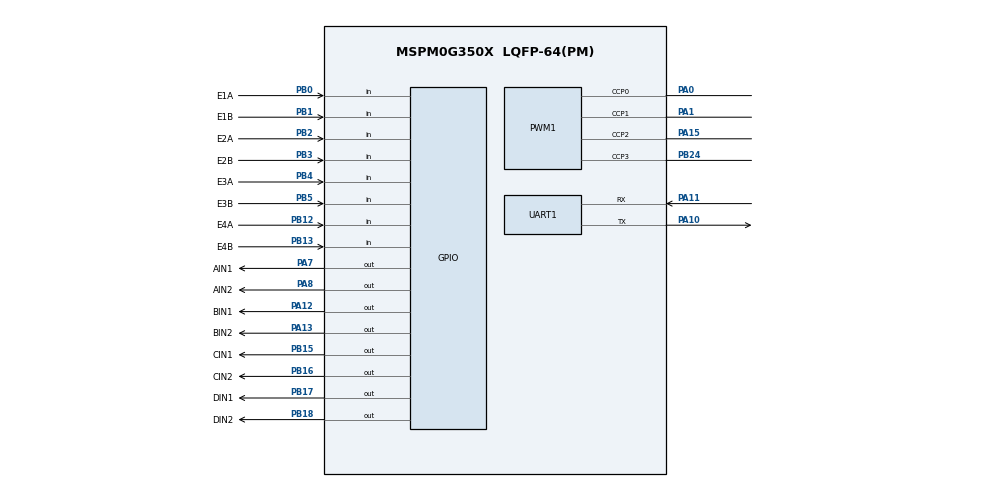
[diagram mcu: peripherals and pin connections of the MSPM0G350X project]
/**
 * @cliArgs --device "MSPM0G350X" --part "Default" --package "LQFP-64(PM)" --product "mspm0_sdk@2.11.00.07"
 * @versions {"tool":"1.27.1+4634"}
 */

/**
 * Import the modules used in this configuration.
 */
const GPIO   = scripting.addModule("/ti/driverlib/GPIO", {}, false);
const GPIO1  = GPIO.addInstance();
const GPIO2  = GPIO.addInstance();
const GPIO3  = GPIO.addInstance();
const GPIO4  = GPIO.addInstance();
const PWM    = scripting.addModule("/ti/driverlib/PWM", {}, false);
const PWM1   = PWM.addInstance();
const SYSCTL = scripting.addModule("/ti/driverlib/SYSCTL");
const TIMER  = scripting.addModule("/ti/driverlib/TIMER", {}, false);
const TIMER1 = TIMER.addInstance();
const UART   = scripting.addModule("/ti/driverlib/UART", {}, false);
const UART1  = UART.addInstance();

/**
 * Write custom configuration values to the imported modules.
 */
const divider9       = system.clockTree["UDIV"];
divider9.divideValue = 2;

const mux4       = system.clockTree["EXHFMUX"];
mux4.inputSelect = "EXHFMUX_XTAL";

const mux8       = system.clockTree["HSCLKMUX"];
mux8.inputSelect = "HSCLKMUX_SYSPLL2X";

const mux12       = system.clockTree["SYSPLLMUX"];
mux12.inputSelect = "zSYSPLLMUX_HFCLK";

const pinFunction4        = system.clockTree["HFXT"];
pinFunction4.inputFreq    = 40;
pinFunction4.enable       = true;
pinFunction4.HFCLKMonitor = true;
pinFunction4.HFXTStartup  = 20;

GPIO1.$name                          = "LED";
GPIO1.associatedPins[0].$name        = "PIN_0";
GPIO1.associatedPins[0].assignedPort = "PORTB";
GPIO1.associatedPins[0].assignedPin  = "22";
GPIO1.associatedPins[0].ioStructure  = "SD";

const Board = scripting.addModule("/ti/driverlib/Board", {}, false);

GPIO2.$name                               = "Encoder";
GPIO2.port                                = "PORTB";
GPIO2.associatedPins.create(8);
GPIO2.associatedPins[0].$name             = "E1A";
GPIO2.associatedPins[0].direction         = "INPUT";
GPIO2.associatedPins[0].internalResistor  = "PULL_UP";
GPIO2.associatedPins[0].interruptEn       = true;
GPIO2.associatedPins[0].polarity          = "RISE_FALL";
GPIO2.associatedPins[0].inputFilter       = "8_CYCLES";
GPIO2.associatedPins[0].interruptPriority = "3";
GPIO2.associatedPins[0].pin.$assign       = "PB0";
GPIO2.associatedPins[1].$name             = "E1B";
GPIO2.associatedPins[1].direction         = "INPUT";
GPIO2.associatedPins[1].internalResistor  = "PULL_UP";
GPIO2.associatedPins[1].interruptEn       = true;
GPIO2.associatedPins[1].polarity          = "RISE_FALL";
GPIO2.associatedPins[1].inputFilter       = "8_CYCLES";
GPIO2.associatedPins[1].interruptPriority = "3";
GPIO2.associatedPins[1].pin.$assign       = "PB1";
GPIO2.associatedPins[2].$name             = "E2A";
GPIO2.associatedPins[2].direction         = "INPUT";
GPIO2.associatedPins[2].internalResistor  = "PULL_UP";
GPIO2.associatedPins[2].interruptEn       = true;
GPIO2.associatedPins[2].polarity          = "RISE_FALL";
GPIO2.associatedPins[2].inputFilter       = "8_CYCLES";
GPIO2.associatedPins[2].interruptPriority = "3";
GPIO2.associatedPins[2].pin.$assign       = "PB2";
GPIO2.associatedPins[3].$name             = "E2B";
GPIO2.associatedPins[3].direction         = "INPUT";
GPIO2.associatedPins[3].internalResistor  = "PULL_UP";
GPIO2.associatedPins[3].interruptEn       = true;
GPIO2.associatedPins[3].polarity          = "RISE_FALL";
GPIO2.associatedPins[3].inputFilter       = "8_CYCLES";
GPIO2.associatedPins[3].interruptPriority = "3";
GPIO2.associatedPins[3].pin.$assign       = "PB3";
GPIO2.associatedPins[4].$name             = "E3A";
GPIO2.associatedPins[4].direction         = "INPUT";
GPIO2.associatedPins[4].internalResistor  = "PULL_UP";
GPIO2.associatedPins[4].interruptEn       = true;
GPIO2.associatedPins[4].polarity          = "RISE_FALL";
GPIO2.associatedPins[4].inputFilter       = "8_CYCLES";
GPIO2.associatedPins[4].interruptPriority = "3";
GPIO2.associatedPins[4].pin.$assign       = "PB4";
GPIO2.associatedPins[5].$name             = "E3B";
GPIO2.associatedPins[5].direction         = "INPUT";
GPIO2.associatedPins[5].internalResistor  = "PULL_UP";
GPIO2.associatedPins[5].interruptEn       = true;
GPIO2.associatedPins[5].polarity          = "RISE_FALL";
GPIO2.associatedPins[5].inputFilter       = "8_CYCLES";
GPIO2.associatedPins[5].interruptPriority = "3";
GPIO2.associatedPins[5].pin.$assign       = "PB5";
GPIO2.associatedPins[6].$name             = "E4A";
GPIO2.associatedPins[6].direction         = "INPUT";
GPIO2.associatedPins[6].internalResistor  = "PULL_UP";
GPIO2.associatedPins[6].interruptEn       = true;
GPIO2.associatedPins[6].polarity          = "RISE_FALL";
GPIO2.associatedPins[6].inputFilter       = "8_CYCLES";
GPIO2.associatedPins[6].interruptPriority = "3";
GPIO2.associatedPins[6].pin.$assign       = "PB12";
GPIO2.associatedPins[7].$name             = "E4B";
GPIO2.associatedPins[7].direction         = "INPUT";
GPIO2.associatedPins[7].internalResistor  = "PULL_UP";
GPIO2.associatedPins[7].interruptEn       = true;
GPIO2.associatedPins[7].polarity          = "RISE_FALL";
GPIO2.associatedPins[7].inputFilter       = "8_CYCLES";
GPIO2.associatedPins[7].interruptPriority = "3";
GPIO2.associatedPins[7].pin.$assign       = "PB13";

GPIO3.$name                         = "Motor_Ctrl_A";
GPIO3.port                          = "PORTA";
GPIO3.associatedPins.create(4);
GPIO3.associatedPins[0].$name       = "AIN1";
GPIO3.associatedPins[0].pin.$assign = "PA7";
GPIO3.associatedPins[1].$name       = "AIN2";
GPIO3.associatedPins[1].pin.$assign = "PA8";
GPIO3.associatedPins[2].$name       = "BIN1";
GPIO3.associatedPins[2].pin.$assign = "PA12";
GPIO3.associatedPins[3].$name       = "BIN2";
GPIO3.associatedPins[3].pin.$assign = "PA13";

GPIO4.$name                         = "Motor_Ctrl_B";
GPIO4.port                          = "PORTB";
GPIO4.associatedPins.create(4);
GPIO4.associatedPins[0].$name       = "CIN1";
GPIO4.associatedPins[0].pin.$assign = "PB15";
GPIO4.associatedPins[1].$name       = "CIN2";
GPIO4.associatedPins[1].pin.$assign = "PB16";
GPIO4.associatedPins[2].$name       = "DIN1";
GPIO4.associatedPins[2].pin.$assign = "PB17";
GPIO4.associatedPins[3].$name       = "DIN2";
GPIO4.associatedPins[3].pin.$assign = "PB18";

PWM1.$name                      = "PWM_0";
PWM1.clockDivider               = 8;
PWM1.timerStartTimer            = true;
PWM1.ccIndex                    = [0,1,2,3];
PWM1.PWM_CHANNEL_0.$name        = "ti_driverlib_pwm_PWMTimerCC0";
PWM1.PWM_CHANNEL_1.$name        = "ti_driverlib_pwm_PWMTimerCC1";
PWM1.ccp0PinConfig.$name        = "ti_driverlib_gpio_GPIOPinGeneric2";
PWM1.ccp1PinConfig.$name        = "ti_driverlib_gpio_GPIOPinGeneric3";
PWM1.peripheral.$assign         = "TIMA0";
PWM1.peripheral.ccp0Pin.$assign = "PA0";
PWM1.peripheral.ccp1Pin.$assign = "PA1";
PWM1.peripheral.ccp2Pin.$assign = "PA15";
PWM1.peripheral.ccp3Pin.$assign = "PB24";
PWM1.PWM_CHANNEL_2.$name        = "ti_driverlib_pwm_PWMTimerCC2";
PWM1.PWM_CHANNEL_3.$name        = "ti_driverlib_pwm_PWMTimerCC3";
PWM1.ccp2PinConfig.$name        = "ti_driverlib_gpio_GPIOPinGeneric0";
PWM1.ccp3PinConfig.$name        = "ti_driverlib_gpio_GPIOPinGeneric1";

SYSCTL.forceDefaultClkConfig = true;

TIMER1.$name              = "TIMER_0";
TIMER1.timerClkDiv        = 8;
TIMER1.timerClkPrescale   = 100;
TIMER1.timerPeriod        = "1ms";
TIMER1.timerMode          = "PERIODIC";
TIMER1.timerStartTimer    = true;
TIMER1.interrupts         = ["ZERO"];
TIMER1.peripheral.$assign = "TIMA1";

UART1.$name                    = "UART_0";
UART1.targetBaudRate           = 115200;
UART1.peripheral.rxPin.$assign = "PA11";
UART1.peripheral.txPin.$assign = "PA10";
UART1.txPinConfig.$name        = "ti_driverlib_gpio_GPIOPinGeneric6";
UART1.rxPinConfig.$name        = "ti_driverlib_gpio_GPIOPinGeneric7";

/**
 * Pinmux solution for unlocked pins/peripherals. This ensures that minor changes to the automatic solver in a future
 * version of the tool will not impact the pinmux you originally saw.  These lines can be completely deleted in order to
 * re-solve from scratch.
 */
pinFunction4.peripheral.$suggestSolution           = "SYSCTL";
pinFunction4.peripheral.hfxInPin.$suggestSolution  = "PA5";
pinFunction4.peripheral.hfxOutPin.$suggestSolution = "PA6";
GPIO1.associatedPins[0].pin.$suggestSolution       = "PB22";
Board.peripheral.$suggestSolution                  = "DEBUGSS";
Board.peripheral.swclkPin.$suggestSolution         = "PA20";
Board.peripheral.swdioPin.$suggestSolution         = "PA19";
SYSCTL.peripheral.$suggestSolution                 = "SYSCTL";
UART1.peripheral.$suggestSolution                  = "UART0";
